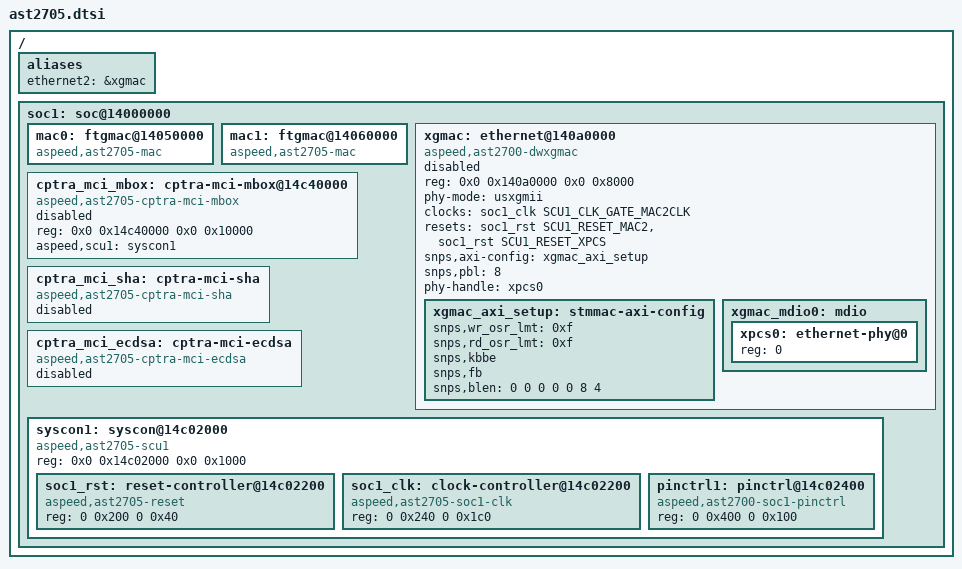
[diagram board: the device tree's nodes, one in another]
// SPDX-License-Identifier: GPL-2.0+
#include "ast2700.dtsi"

/ {
	aliases {
		ethernet2 = &xgmac;
	};

	soc1: soc@14000000 {
		mac0: ftgmac@14050000 {
			compatible = "aspeed,ast2705-mac", "faraday,ftgmac100";
		};

		mac1: ftgmac@14060000 {
			compatible = "aspeed,ast2705-mac", "faraday,ftgmac100";
		};

		/delete-node/ ftgmac@14070000;

		xgmac: ethernet@140a0000 {
			compatible = "aspeed,ast2700-dwxgmac", "snps,dwxgmac-2.10", "snps,dwxgmac";
			reg = <0x0 0x140a0000 0x0 0x8000>;
			phy-mode = "usxgmii";
			clocks = <&soc1_clk SCU1_CLK_GATE_MAC2CLK>;
			clock-names = "stmmaceth";
			resets = <&soc1_rst SCU1_RESET_MAC2>,
				 <&soc1_rst SCU1_RESET_XPCS>;
			reset-names = "stmmaceth", "ahb";
			snps,axi-config = <&xgmac_axi_setup>;
			snps,pbl = <8>;
			phy-handle = <&xpcs0>;
			status = "disabled";

			xgmac_axi_setup: stmmac-axi-config {
				snps,wr_osr_lmt = <0xf>;
				snps,rd_osr_lmt = <0xf>;
				snps,kbbe;
				snps,fb;
				snps,blen = <0 0 0 0 0 8 4>;
			};

			xgmac_mdio0: mdio {
				#address-cells = <1>;
				#size-cells = <0>;

				xpcs0: ethernet-phy@0 {
					reg = <0>;
				};
			};
		};

		cptra_mci_mbox: cptra-mci-mbox@14c40000 {
			compatible = "aspeed,ast2705-cptra-mci-mbox";
			reg = <0x0 0x14c40000 0x0 0x10000>;
			aspeed,scu1 = <&syscon1>;
			status = "disabled";
		};

		cptra_mci_sha: cptra-mci-sha {
			compatible = "aspeed,ast2705-cptra-mci-sha";
			status = "disabled";
		};

		cptra_mci_ecdsa: cptra-mci-ecdsa {
			compatible = "aspeed,ast2705-cptra-mci-ecdsa";
			status = "disabled";
		};

		syscon1: syscon@14c02000 {
			compatible = "aspeed,ast2705-scu1", "syscon", "simple-mfd";
			reg = <0x0 0x14c02000 0x0 0x1000>;
			ranges = <0 0 0 0x14c02000 0 0x1000>;
			#address-cells = <2>;
			#size-cells = <2>;

			soc1_rst: reset-controller@14c02200 {
				compatible = "aspeed,ast2705-reset";
				reg = <0 0x200 0 0x40>;
				#reset-cells = <1>;
			};

			soc1_clk: clock-controller@14c02200 {
				compatible = "aspeed,ast2705-soc1-clk";
				reg = <0 0x240 0 0x1c0>;
				#clock-cells = <1>;
			};

			pinctrl1: pinctrl@14c02400 {
				compatible = "aspeed,ast2700-soc1-pinctrl";
				reg = <0 0x400 0 0x100>;
			};
		};
	};
};
